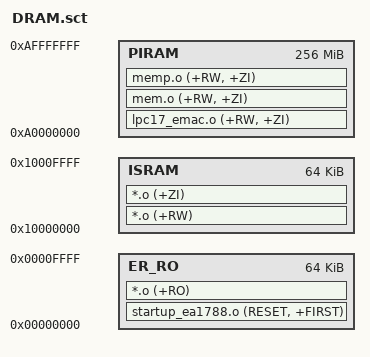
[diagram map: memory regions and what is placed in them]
;-------------------------------------------------------------------------------------
;   Keil scatter loading file
;-------------------------------------------------------------------------------------

; Load region is in internal FLASH, 256KBytes
FLASH 0x00000000 0x40000 {
  ; All code and RO data in in FLASH
  ER_RO 0x00000000 0x10000 {
    startup_ea1788.o (RESET, +FIRST)
    *.o (+RO)
  }

    ; All non-DMA related RW/ZI data is in internal IRAM
  ISRAM 0x10000000 0x10000 {
    *.o (+RW)
    *.o (+ZI)
  }

  ; DMA buffers need to be located in peripheral RAM, but not pbufs
  PIRAM 0xA0000000 0x10000000 {
    lpc17_emac.o (+RW, +ZI)
	mem.o (+RW, +ZI)
	memp.o (+RW, +ZI)
  }
}
